# RL6955_IP_SVD register map
Vendor: Realtek
Registers are 32-bit, read-write, reset 0x0 unless marked. A register's access mark holds for its fields unless they carry their own. Offsets are from the block's base; [hi:lo] are bit positions; {n}, {i} and the like mark numbered series; <NAME> marks a mode.

## PSRAM_REG (part 2 of 2)
Base 0x41909000
Same registers: SPI_FLASH_CTRL 0x4190B000
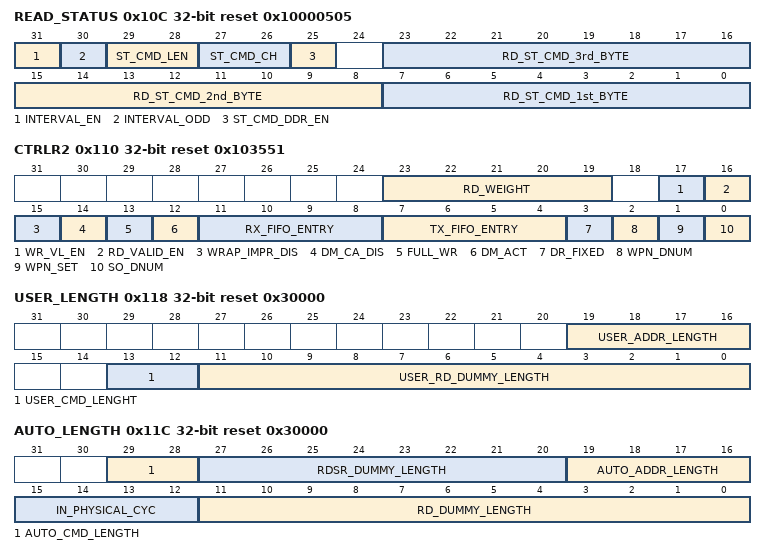
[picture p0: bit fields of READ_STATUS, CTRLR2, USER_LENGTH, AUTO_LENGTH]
0x10C READ_STATUS reset 0x10000505 — Read Status Command of SPI Flash
  [31] INTERVAL_EN — Set to enable INTERVAL_ODD. Available only if configuration of SPIC_LITE is not defined (SPIC Full ver).
  [30] INTERVAL_ODD — Indicates SPI Flash read status with 2-Byte status but checking only odd byte or even byte. 0: even byte (2, 4, 6, ...) 1: odd byte (1, 3, 5, ...) Available only if configuration of SPIC_LITE is not defined (SPIC Full ver).
  [29:28] ST_CMD_LEN — Indicates the number of bytes in read status command. ST_CMD_LEN can be 1~3. Available only if configuration of SPIC_LITE is not defined (SPIC Full ver).
  [27:26] ST_CMD_CH — Indicates channel number of read status command in transmitting and receiving data. 0: single channel 1: dual channels 2: quad channels 3: octal channel
  [25] ST_CMD_DDR_EN — Indicates the DDR mode in ST_CMD_CH. Available only if configuration of DDR_EN is defined.
  [23:16] RD_ST_CMD_3rd_BYTE — Indicates SPI Flash command value of 3rd byte of read status. Available only if configuration of SPIC_LITE is not defined (SPIC Full ver).
  [15:8] RD_ST_CMD_2nd_BYTE — Indicates SPI Flash command value of 2nd byte of read status. Available only if configuration of SPIC_LITE is not defined (SPIC Full ver).
  [7:0] RD_ST_CMD_1st_BYTE — Indicates SPI Flash command value of 1st byte of read status.
0x110 CTRLR2 reset 0x103551 — Control Register 2
  [23:19] RD_WEIGHT — Set to determine the read and write priority. RD_WEIGHT should >= 2 (if set to 0 or 1, RD_WEIGHT will use the previous value). Ex: if RD_WEIGHT = 5, SPIC will accept 1 write cmd after accepting 4 read cmd.
  [17] WR_VL_EN — Set to enable variable write latency. SPIC will set variable write latency according to RWDS. If WR_VL_EN = 0, SPIC will set fix write latency.
  [16] RD_VALID_EN — Set to enable variable read latency. SPIC will not sample read data until rx_data_valid = 1. If RD_VALID_EN = 0, SPIC will sample read data according to internal counter.
  [15] WRAP_IMPR_DIS — Set to disable wrap_align function (convert wrap to incremental through aligning start address to burst boundary) in auto mode. If DIS_WRAP_ALIGN = 1, SPIC will chop wrap transation into two incremental transactions.
  [14] DM_CA_DIS — Set to disable spi_dm_oe_n (let the device to drive DM) when SPIC pushing CMD and ADDR for both user mode and auto mode. Used to implement write variable latency in Winbond psram.
  [13] FULL_WR — Set to enable full write in both user mode and auto mode. If FULL_WR=1, SPIC will ignore pushing DM_DR in user mode. If FULL_WR = 0, SPIC will use spi_dm to do partial write in auto mode. Available only if configuration of DM_EN is defined.
  [12] DM_ACT — DM (Data Mask) is active high or low, which is defined by specific PSRAM SPEC. If DM is active high (DM=1 means "don't write"), DM_ACT should be set to 1 and the corresponding byte of write data will not be written into the PSRAM. Available only if configuration of DM_EN is defined.
  [11:8] RX_FIFO_ENTRY — If using SPIC_HAS_DMA (NO_MERGE_FIFO) SPIC, this field indicates the valid entry of RX FIFO. It is an index of 2 and it should be equal or smaller than 5. The user can modify it to profile with a different entry. Ex: if RX_FIFO entry is 32, RX_FIFO_ENTYR <=5.
  [7:4] TX_FIFO_ENTRY — If using SPIC_HAS_DMA (NO_MERGE_FIFO) SPIC, this field indicates the valid entry of TX_FIFO. If using MERGE_FIFO SPIC, there is only one FIFO is in the SPIC design, and this field indicates the valid entry of the FIFO. It is an index of 2 and it should be equal or smaller than FIFO_ABW. The user can modify it to profile with a different entry. Ex: if FIFO entry is 32, FIFO_ENTYR <=5.
  [3] DR_FIXED — Indicate the AXI FIXED read mode on DR. (after 2021/01). It can only work on address that aligns to request size. Ex: (1) arsize=0, addr[1:0] can be 00, 01, 10, 11 (2) arsize=1, addr[1:0] can be 00, 10 (3) arsize=2, addr[1:0] can be 00. If setting 1, user mode read DR will be FIXED. Otherwise, user mode read DR will be INCR.
  [2] WPN_DNUM — Indicates the WPn input pin of SPI Flash is connected to spi_sout[2]or [3]. If setting 0, it connects to spi_sdata[2]. Otherwise, it connects to spi_sdata[3].
  [1] WPN_SET — To implement write protect function. spi_wen_out and the bit of spi_sout which connects to WPN would be initial to 0. WPN_SET: If setting 1 is protected. Otherwise, is not protected.(Configuration Form is using "WPN_SET_n": If setting 1 is NOT protected. Otherwise, is protected.)
  [0] SO_DNUM — Indicates SO input pin of SPI Flash is connected to spi_sout[0]or [1]. It refers to SPI Flash and also the system connection with SPI_Flash (see 6.1.3) If setting 0, it connects to spi_sout[0] (single-channel connection). Otherwise, it connects to spi_sout[1] (multi-channels connection). (Default is configured to 1to support multi-channel connection)
0x114 FBAUDR reset 0x1 — Fast Baud Rate Select
  [11:0] FSCKDV — Indicate the divider of Fast read command when FAST_RD is setting in user mode or using fast read command in auto mode. The frequency of spi_sclk is derived from: Frequency of spi_sclk = Frequency of bus_clk/(2*FSCKDV).
0x118 USER_LENGTH reset 0x30000
  [19:16] USER_ADDR_LENGTH — Indicates number of bytes in address phase (between command phase and write/read phase) in user mode. If it is set to 4, it will transmit 4-byte Address to support 4-byte address mode in SPI Flash.
  [13:12] USER_CMD_LENGHT — Indicates number of bytes in command phase in user mode. USER_CMD_LENGHT can be 0~3.
  [11:0] USER_RD_DUMMY_LENGTH — Indicates delay cycles for receiving data in user mode (USER_MODE == 1). It is referenced by bus_clk.
0x11C AUTO_LENGTH reset 0x30000 — Auto Address Length Register
  [29:28] AUTO_CMD_LENGTH — Indicate byte numbers of read/write command in auto mode. AUTO_CMD_LENGTH should be 1 or 2 bytes. Note: If set 0, it will transmit 1 byte command to device. Exists: TAG >= 2.0.8.
  [27:20] RDSR_DUMMY_LENGTH — Indicates delay cycles for receiving data after Read Status Register (RDSR) command. (auto write or user mode with auto check) It is referenced by bus_clk.
  [19:16] AUTO_ADDR_LENGTH — Indicates number of bytes address in read/write command in auto mode. AUTO_ADDR_LENGTH should be 1, 2, 3, 4 bytes. If it is set to 4, it will transmit 4-byte Address to support 4-byte address mode in SPI Flash. Note: PRM in auto mode should set VALID_CMD[11] (PRM_EN) with correct AUTO_ADDR_LENGTH.
  [15:12] IN_PHYSICAL_CYC — Indicates how many SPIC CLK (bus_clk) cycles from pad to internal SPIC. It is used in both auto mode and user mode.
  [11:0] RD_DUMMY_LENGTH — Indicates delay cycles for receiving data. It is referenced by bus_clk. Note: Don't include SPIC CLK (bus_clk) cycles from pad to internal SPIC
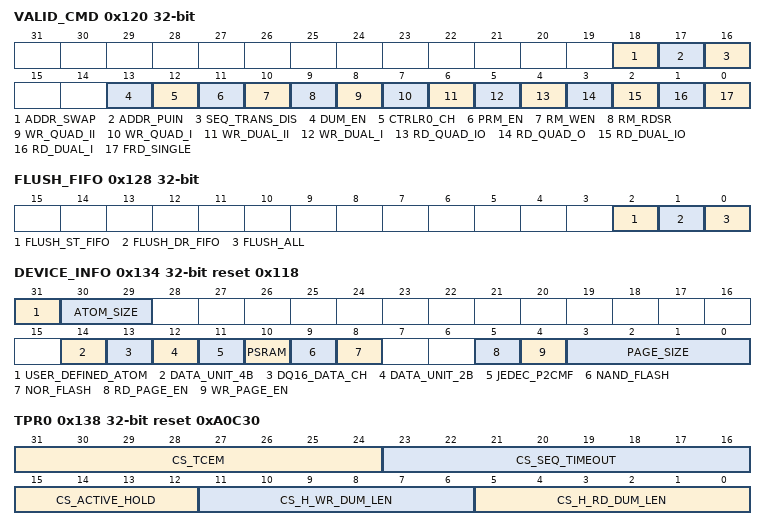
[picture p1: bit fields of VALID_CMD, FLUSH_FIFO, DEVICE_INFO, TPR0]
0x120 VALID_CMD — Valid Command Register
  [18] ADDR_SWAP — Set to enable address swap based on CR.FLASH_SIZE in auto mode If address swap is enable, memory space is divided by two and address will be swapped between two spaces ex. if CR.FLASH_SIZE is 0x9, axi_axaddr is 0x00000000. The real address transmitted to device will be 0x00800000 Exists: TAG >= 2.0.14.
  [17] ADDR_PUIN — Set (1) to pull in first address to negedge of spi_clk. (negedge of last cmd) Set (0) indicate first address start at next posedge of last cmd phase. Used when DDR address and need to pull in address. Exists: TAG >= 2.0.6.
  [16] SEQ_TRANS_DIS — Set (1) to disable sequential read and sequential write function in auto mode. If two bus read/write transactions are sequential (address is consecutive), SPIC can access second transaction data without sending CMD/ADDR/DUMMY. Once disable (1) this bit field, spi_csn will inactive immediately and also disable this function.
  [13] DUM_EN — Enable to push one dummy byte (DUM_BYTE_VAL) after pushing address to Flash in auto read. If PRM_EN is active, it will push PRM_Value instead of DUM_BYTE_VAL. If RD_DUMMY_LENGTH = 0, it won't push the dummy byte.
  [12] CTRLR0_CH — Set (1) to use CTRLR0 CMD_CH/DATA_CH/ADDR_CH and DDR_EN field in Auto mode; Otherwise, SPIC will decode according to which VALID_CMD you choose in auto mode. Suggestion while use this bit field: Read Flash mode: (1-4-8), (4-4-8), (1-4D-8D), (4-4D-8D) with using RD_QUAD_IO[7:0] Read Flash mode (with 2-Byte CMD): (1-8-8), (8-8-8), (8D-8D-8D), (4D-4D-4D) with using RD_FAST_SINGLE_IO[15:0] (always using FBAUD) Write Flash mode: (1-4-8), (4-4-8) with using WR_QUAD_IO[7:0] Write Flash mode (with 2-Byte CMD): (1-8-8), (8-8-8), (8D-8D-8D) with using WR_SINGLE_IO[15:0]
  [11] PRM_EN — Set to enable SPIC performance read mode in Auto Mode. RXI-312 SPIC will auto exit performance read mode before auto write or enter to user mode. Enter PRM Flow: 1. Set CR_VALID_CMD[11] (PRM_EN) with CR_VALID_CMD[4] (RD_QUAD_IO) or with (CR_VALID_CMD[0] and CR_VALID_CMD[12]) 2. Set CR_READ_QUAD_ADDR_DATA[23:16] (PRM_VALUE) and [7:0] (RD_QUAD_IO_CMD) 3. Set correct Dummy Cycle, and Valid Command then access in Auto Mode address range If PRM_EN, at 1st time Auto Rd, it will access with CMD, and store this condition. At 2nd Auto Rd or later, it will access without CMD but with Address and Mode Value. Our SPIC will check PRM_VALUE (CR_READ_QUAD_ADDR_DATA [23:16]), if PRM_VALUE ==00 (not a valid PRM value), and PRM_EN is set, SPIC will always access SPI Flash with (CMD+ADDR+MODE+DUMMY+...) format.
  [10] RM_WEN — Remove write enable command in auto write.
  [9] RM_RDSR — Remove read status register in auto write.
  [8] WR_QUAD_II — Indicates quad address/data write is a valid command to execute. (known as (1-4-4))
  [7] WR_QUAD_I — Indicates quad data write is a valid command to execute. (known as (1-1-4))
  [6] WR_DUAL_II — Indicates dual address/data write is a valid command to execute. (known as (1-2-2))
  [5] WR_DUAL_I — Indicates dual data write is a valid command to execute. (known as (1-1-2))
  [4] RD_QUAD_IO — Indicates quad address/data read is a valid command to execute. (known as (1-4-4))
  [3] RD_QUAD_O — Indicates quad data read is a valid command to execute. (known as (1-1-4))
  [2] RD_DUAL_IO — Indicates dual address/data read is a valid command to execute. (known as (1-2-2))
  [1] RD_DUAL_I — Indicates dual data read is a valid command to execute. (known as (1-1-2))
  [0] FRD_SINGLE — Indicates fast read command is a valid command to execute. (known as (1-1-1))
0x124 FLASE_SIZE reset 0xC — Flash Size Register
  [4:0] FLASH_SIZE — Indicate the size of flash size to select the target SPI Flash in auto mode. (flash size unit is byte) If TAG >= 2.0.3: CR_FLASH_SIZE = log2 (flash size) -15. Ex: flash size is 4MB, CR_FLASH_SIZE = log2 (4MB) -15 = 22 - 15 = 7
0x128 FLUSH_FIFO wo
  [2] FLUSH_ST_FIFO — Clear all data in the ST_FIFO when writing to FLUSH_ST_FIFO register.
  [1] FLUSH_DR_FIFO — Clear all data in the TX_FIFO and RX_FIFO when writing to FLUSH_DR_FIFO register.
  [0] FLUSH_ALL — Clear all data in all FIFO (include TX_FIFO, RX_FIFO and ST_FIFO) and reset all FSM when writing to FLUSH_ALL register.
0x12C DUM_BYTE — Dummy byte value
  [7:0] DUM_BYTE_VAL — Push dummy byte value.
0x130 TX_NDF
  [23:0] TX_NDF — Indicates a number of data frames (Unit: Byte). After transmitting command and address, SPIC transmits data continuously until data frames are equal to TX_NDF. TX_NDF can set larger than TX_FIFO size.
0x134 DEVICE_INFO reset 0x118
  [31] USER_DEFINED_ATOM — Enable user defined DEVICE_INFO[30:29].ATOM_SIZE 1: users can program ATOM_SIZE 0: SPIC sets ATOM_SIZE dynamically Exists: TAG >= 2.0.12.
  [30:29] ATOM_SIZE — Indicate the atomic size of read/write transactions 2'b00: 1 byte 2'b01: 2 byte 2'b10: 4 byte 2'b11: 3 byte The equation of atomic size: data_channel * data_rate e.g., if DQ16 and DDR, atomic size is (16*2/8) = 4 byte *Minimun atomic size is 1 byte *For exception of this equaltion, refer to PSRAM Format for devices with special requirements For TAG < 2.0.12, ATOM_SIZE is [7:6] and is set automatically by SPIC
  [14] DATA_UNIT_4B — Set (1) when the SPI device stores 4-byte data for each address. Available only if configuration of PSRAM_EN is defined.
  [13] DQ16_DATA_CH — Set (1) when DQ16 PSRAM uses 16-bit data channel. When DQ16_DATA_CH = 1'b1, set CTRLR0[19:18] DATA_CH = 2'b00.
  [12] DATA_UNIT_2B — Set (1) when the SPI device stores 2-byte data for each address. Available only if configuration of PSRAM_EN is defined.
  [11] JEDEC_P2CMF — Set (1) when the SPI cmd is JEDEC Profile 2.0 Command Modifier Formats. (6-byte command and address) Available only if configuration of PSRAM_EN is defined.
  [10] PSRAM — Set (1) when the SPI device is PSRAM. PSRAM will disable WEN and RDSR in auto write. Available only if configuration of PSRAM_EN is defined.
  [9] NAND_FLASH — Set (1) when the SPI device is NAND Flash. (not support yet) Available only if configuration of NAND_EN is defined.
  [8] NOR_FLASH — Set (1) when the SPI device is NOR Flash.
  [5] RD_PAGE_EN — Enable SPIC to chop the burst read command across page boundaries in auto mode.
  [4] WR_PAGE_EN — Enable SPIC to chop the burst write command across page boundaries in auto mode.
  [3:0] PAGE_SIZE — The page size of device (byte) = 2^(PAGE_SIZE) The minimum value of page size is 128-byte. Please set PAGE_SIZE >= 7. ex. If the page size of device is 256-byte, PAGE_SIZE should be set to 8. 0x7: 128-byte 0x8: 256-byte 0x9: 512-byte 0xa: 1024-byte 0xb: 2048-byte 0xc: 4096-byte
0x138 TPR0 reset 0xA0C30 — Timing parameters
  [31:24] CS_TCEM — Set to chop auto cmd when CSN low pulse width = (CS_TCEM*32) bus_clk. If set CS_TCEM = 0 will disable this function. ex. PSRAM tCEM = 4us, SPIC frequency = 100Mhz. CS_TCEM = ((4000 ns/10 ns)/32) - BYTE_DELAY = 12 (c) - BYTE_DELAY If ((16*baud_rate)/data_channel) <=32. BYTE_DELAY = 0. If ((16*baud_rate)/data_channel) > 32. BYTE_DELAY = (((16*baud_rate)/data_channel) - 32)/32. ex. If baud_rate = 3, data_channel = 1. BYTE_DELAY = (((16*3)/1) - 32)/32 = 16/32 = 0.5 Therefore, BYTE_DELAY should be 1 in this example. Note: Available only if configuration of PSRAM_EN is defined.
  [23:16] CS_SEQ_TIMEOUT — The timeout setting of auto command after sequential read command. If set CS_SEQ_TIMEOUT = 00 will disable this function. If set CS_SEQ_TIMEOUT > 00, SPIC will exit sequential transaction read and inactive CS when there is no auto read/write command for (CS_SEQ_TIMEOUT *4) bus_clocks.
  [15:12] CS_ACTIVE_HOLD — For Flash chip select active hold time after SCLK rising edge (refer to tSLCH/CHSH, tCSS/tCSH) Note: Wait most 16 bus_clk cycles before CS inactive. (Implement CS_ACTIVE_Hold timing only, CS_ACTIVE_Setup timing using D-PHY to shift)
  [11:6] CS_H_WR_DUM_LEN — Dummy cycle between sending write command to SPI Flash. Using the dummy cycles to avoid the timing violation of CS high time.
  [5:0] CS_H_RD_DUM_LEN — Dummy cycle between sending read command to SPI Flash. Using the dummy cycles to avoid the timing violation of CS high time.
0x13C AUTO_LENGTH2 — Auto Address Length Register 2
  [11:0] WR_DUMMY_LENGTH — Indicates delay cycles for transmitting data in auto mode. It is referenced by bus_clk. Available only if configuration of PSRAM_EN is defined.
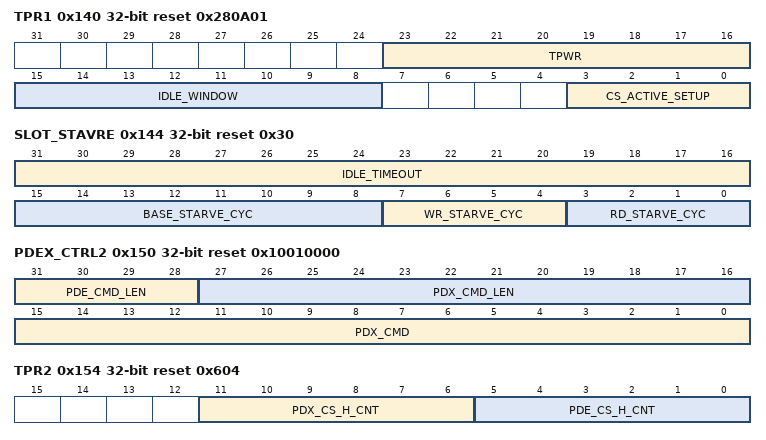
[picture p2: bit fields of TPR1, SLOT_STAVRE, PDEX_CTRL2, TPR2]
0x140 TPR1 reset 0x280A01 — Timing Parameters Register 1
  [23:16] TPWR — It is used to configure the cycle counts before spi_csn becomes low when spi_pwr turns from low to high.
  [15:8] IDLE_WINDOW — It is used to configure the cycle counts before turn off the spi_pwr when SPIC is IDLE.
  [3:0] CS_ACTIVE_SETUP — It is used to configure the setup time before the first edge (rising edge for mode0 and falling edge for mode3) of spi_sclk(refer to tCSS or tSLCH ). Note: It can't be configured 0 (if you configure 0 to this 4 bits field, this field will not be updated).
0x144 SLOT_STAVRE reset 0x30 — Slot Starvation Control Register
  [31:16] IDLE_TIMEOUT — If the current slot has no command and another slot has command, or both write/read slot have no command and current slot is write slot, to wait IDLE_TIMEOUT cycles and turnaround slot if current slot still has no command Exists: TAG >= 2.0.5.
  [15:8] BASE_STARVE_CYC — This is basic starvation counter cycles for WR_STARVE_CYC and RD_STARVE_CYC. Exists: TAG >= 2.0.5.
  [7:4] WR_STARVE_CYC — The timeout of write slot would be set when write cmd is no servicing in the interval time= (WR_STARVE_CYC+1) x (BASE_STARVE_CYC+1) Exists: TAG >= 2.0.5.
  [3:0] RD_STARVE_CYC — The timeout of read slot would be set when read cmd is no servicing in the interval time= (RD_STARVE_CYC+1) x (BASE_STARVE_CYC+1) Exists: TAG >= 2.0.5.
0x148 PDEX_CTRL0 — PDEX Control Register 0
  [31:0] PDE_CMD0 — Indicate the [3-0] byte of SPI PDE command value. Exists: TAG >= 2.0.5. Available only if configuration of SPI_PDEX_ENABLE is defined.
0x14C PDEX_CTRL1 — PDEX Control Register 1
  [31:0] PDE_CMD1 — Indicate the [7-4] byte of SPI PDE command value. Exists: TAG >= 2.0.5. Available only if configuration of SPI_PDEX_ENABLE is defined.
0x150 PDEX_CTRL2 reset 0x10010000 — PDEX Control Register 2
  [31:28] PDE_CMD_LEN — Indicate the SPI PDE command length. The PDE command length indicates the valid command in PDE_CMD0 and PDE_CMD1 Exists: TAG >= 2.0.5. Available only if configuration of SPI_PDEX_ENABLE is defined.
  [27:16] PDX_CMD_LEN — Indicate the SPI PDX command length. The PDE command length indicates the valid command in PDX_CMD. If device is PSRAM, the equation is CR_PDX_CMD_LEN = (SPIC_CLK_FRQ * tXDPD)/1000. (SPIC_CLK_FRQ unit is MHz, tXDPD unit is ns) Exists: TAG >= 2.0.5. Available only if configuration of SPI_PDEX_ENABLE is defined.
  [15:0] PDX_CMD — Indicate the [1-0] byte of SPI PDX command value. If device is PSRAM, PDX command value is not care. Exists: TAG >= 2.0.5. Available only if configuration of SPI_PDEX_ENABLE is defined.
0x154 TPR2 reset 0x604 — Timing Parameters Register 2
  [11:6] PDX_CS_H_CNT — Indicate the time of cs required keep high after PDX The expression of PDX_CS_H_CNT is following PDX_CYCLE_NUM = SPIC_CLK_FRQ * tDP (unit of SPIC_CLK_FRQ is MHz, and tDP is us). If 768>=PDX_CYCLE_NUM > 0, CR_PDX_CS_H_CNT = ceil (PDE_CYCLE_NUM/256). If 15872>=PDX_CYCLE_NUM > 768, CR_PDX_CS_H_CNT = ceil (PDE_CYCLE_NUM/512). If 524288>=PDX_CYCLE_NUM > 15872, CR_PDX_CS_H_CNT = ceil (PDE_CYCLE_NUM/16384) + 31. Ex: SPIC_CLK_FRQ = 400MHz, tDP = 100us, so PDX_CYCLE_NUM = 400*100=40000 524288 >= 40000 > 15872, so CR_PDX_CS_H_CNT = ceil(40000/512) + 31= 3+31 = 34. Exists: TAG >= 2.0.5. Available only if configuration of SPI_PDEX_ENABLE is defined.
  [5:0] PDE_CS_H_CNT — Indicate the time of cs required keep high after PDE The expression of PDE_CS_H_CNT is following PDE_CYCLE_NUM = SPIC_CLK_FRQ * tDP ( unit of SPIC_CLK_FRQ is MHz, and tDP is us). If 768>=PDX_CYCLE_NUM > 0, CR_PDX_CS_H_CNT = ceil (PDE_CYCLE_NUM/256). If 15872>=PDX_CYCLE_NUM > 768, CR_PDX_CS_H_CNT = ceil (PDE_CYCLE_NUM/512). If 524288>=PDX_CYCLE_NUM > 15872, CR_PDX_CS_H_CNT = ceil (PDE_CYCLE_NUM/16384) + 31. Ex: SPIC_CLK_FRQ = 400MHz, tDP = 100us, so PDX_CYCLE_NUM = 400*100=40000 524288 >= 40000 > 15872, so CR_PDX_CS_H_CNT = ceil(40000/512) + 31= 3+31 = 34. Exists: TAG >= 2.0.5. Available only if configuration of SPI_PDEX_ENABLE is defined.
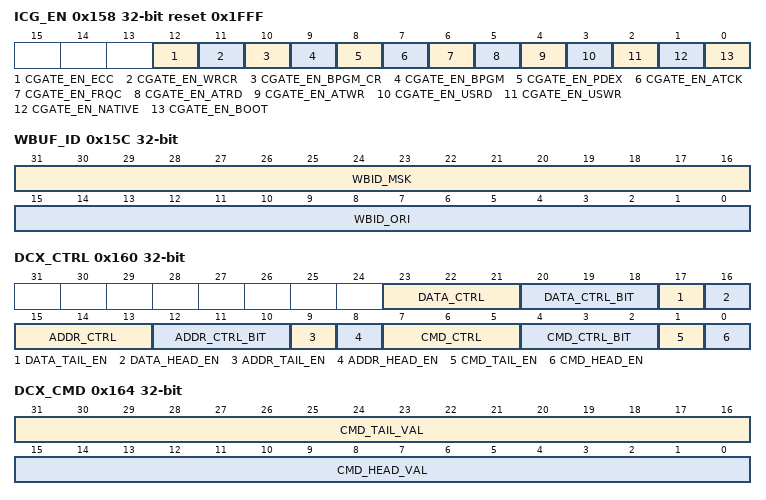
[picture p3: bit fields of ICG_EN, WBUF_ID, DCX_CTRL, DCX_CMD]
0x158 ICG_EN reset 0x1FFF — Clock gating enable control register
  [12] CGATE_EN_ECC — Nand ECC controller module clock gating enable. Exists: TAG >= 2.0.11
  [11] CGATE_EN_WRCR — Write cr module clock gating enable
  [10] CGATE_EN_BPGM_CR — bpgm_cr module clock gating enable
  [9] CGATE_EN_BPGM — bpgm module clock gating enable
  [8] CGATE_EN_PDEX — pdex module clock gating enable
  [7] CGATE_EN_ATCK — atck module clock gating enable
  [6] CGATE_EN_FRQC — frqc module clock gating enable
  [5] CGATE_EN_ATRD — Auto read module clock gating enable
  [4] CGATE_EN_ATWR — Auto write module clock gating enable
  [3] CGATE_EN_USRD — User read module clock gating enable
  [2] CGATE_EN_USWR — User write module clock gating enable
  [1] CGATE_EN_NATIVE — Native chop module clock gating enable
  [0] CGATE_EN_BOOT — Boot module clock gating enable
0x15C WBUF_ID — WBUF ID control register
  [31:16] WBID_MSK — WBID_ORI bit mask. 0: Interrupt bit is masked. 1: Interrupt bit enable.
  [15:0] WBID_ORI — Indicate the awid prior mask are able to push to WBUF in write buffer function. Example: If awid = 0x80 ~ 0x8f are able to push to WBUF. Set WBID_ORI = 0x80 Set WBID_MSK = 0xfff0
0x160 DCX_CTRL — LCDC DCX control register
  [23:21] DATA_CTRL — This field can only be active when DATA_CTRL_BIT is not 0. 0: only one DCX control bit in data phase; 1: DCX control bit for each byte in data phase; 2: DCX control bit for every 2-byte in data phase; 3: DCX control bit for every 4-byte in data phase; 4: DCX control bit for every 8-byte in data phase; 5: DCX control bit for every 16-byte in data phase;
  [20:18] DATA_CTRL_BIT — DCX control bit for data phase. 0: independent DCX signal 1: DCX control bit = 1-bit; 2: DCX control bit = 2 bit; 3: DCX control bit = 4-bit; 4: DCX control bit = 8-bit; 5: DCX control bit = 16-bit;
  [17] DATA_TAIL_EN — 0: without tail in data phase 1: insert tail in data phase
  [16] DATA_HEAD_EN — 0: without header in data phase 1: insert header in data phase
  [15:13] ADDR_CTRL — This field can only be active when ADDR_CTRL_BIT is not 0. 0: only one DCX control bit in addr phase; 1: DCX control bit for each byte in addr phase; 2: DCX control bit for every 2-byte in addr phase; 3: DCX control bit for every 4-byte in addr phase; 4: DCX control bit for every 8-byte in addr phase; 5: DCX control bit for every 16-byte in addr phase;
  [12:10] ADDR_CTRL_BIT — DCX control bit for addr phase. 0: independent DCX signal 1: DCX control bit = 1-bit; 2: DCX control bit = 2 bit; 3: DCX control bit = 4-bit; 4: DCX control bit = 8-bit; 5: DCX control bit = 16-bit;
  [9] ADDR_TAIL_EN — 0: without tail in address phase 1: insert tail in address phase
  [8] ADDR_HEAD_EN — 0: without header in address phase 1: insert header in address phase
  [7:5] CMD_CTRL — This field can only be active when CMD_CTRL_BIT is not 0. 0: only one DCX control bit in cmd phase; 1: DCX control bit for each byte in cmd phase; 2: DCX control bit for every 2-byte in cmd phase; 3: DCX control bit for every 4-byte in cmd phase; 4: DCX control bit for every 8-byte in cmd phase; 5: DCX control bit for every 16-byte in cmd phase;
  [4:2] CMD_CTRL_BIT — DCX control bit for cmd phase. 0: independent DCX signal 1: DCX control bit = 1-bit; 2: DCX control bit = 2 bit; 3: DCX control bit = 4-bit; 4: DCX control bit = 8-bit; 5: DCX control bit = 16-bit;
  [1] CMD_TAIL_EN — 0: without tail in cmd phase 1: insert tail in cmd phase
  [0] CMD_HEAD_EN — 0: without header in cmd phase 1: insert header in cmd phase
0x164 DCX_CMD — LCDC cmd phase DCX control bit value register
  [31:16] CMD_TAIL_VAL — Value of DCX tail control bit in cmd phase.
  [15:0] CMD_HEAD_VAL — Value of DCX header control bit in cmd phase. In 4-wire format cmd phase, spi_dcx = CMD_HEAD_VAL[0].
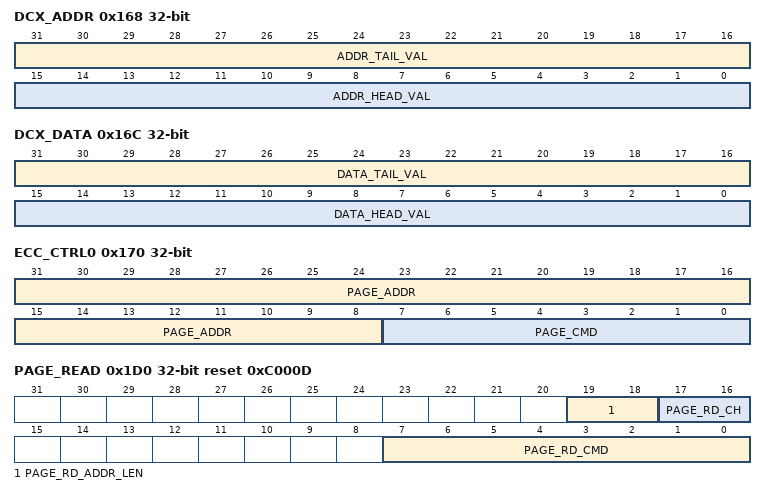
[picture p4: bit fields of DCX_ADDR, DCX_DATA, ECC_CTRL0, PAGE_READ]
0x168 DCX_ADDR — LCDC address phase DCX control bit value register
  [31:16] ADDR_TAIL_VAL — Value of DCX tail control bit in address phase.
  [15:0] ADDR_HEAD_VAL — Value of DCX header control bit in address phase. In 4-wire format address phase, spi_dcx = ADDR_HEAD_VAL[0].
0x16C DCX_DATA — LCDC data phase DCX control bit value register
  [31:16] DATA_TAIL_VAL — Value of DCX tail control bit in data phase.
  [15:0] DATA_HEAD_VAL — Value of DCX header control bit in data phase. In 4-wire format data phase, spi_dcx = DATA_HEAD_VAL[0].
0x170 ECC_CTRL0 — NAND ECC control Register 0
  [31:8] PAGE_ADDR — NAND Page address setting. Exists: TAG >= 2.0.11
  [7:0] PAGE_CMD — NAND page command setting. Ex. READ: Page Data Read (13h) WRITE: Page Execute (10h) Exists: TAG >= 2.0.11
0x174 ECC_CTRL1 — NAND ECC control Register 1
  [7:0] DATA_CMD — NAND data command setting. Ex. READ: Read data (03h) WRITE: Load Program Data (02h) Exists: TAG >= 2.0.11
{0x180+4i} ST_DR{i} ro (i=0..15) — Status Data Register {i}
  [7:0] ST_DR{i} — It is a data buffer with 8-bit width FIFO.
0x1C0 STFLR ro — Status FIFO level Register
  [3:0] STFLR — Status FIFO level. Indicates the FIFO entries of valid data in status data. Note: Available only if configuration of NAND_EN is defined.
0x1D0 PAGE_READ reset 0xC000D — Page Read Command of NAND Flash
  [19:18] PAGE_RD_ADDR_LEN — Indicates number of bytes in address phase in page read command. Available only if configuration of NAND_EN is defined.
  [17:16] PAGE_RD_CH — Indicates channel number of command and address phase in transmitting page read command. 0: single channel 1: dual channels 2: quad channels 3: octal channel Available only if configuration of NAND_EN is defined.
  [7:0] PAGE_RD_CMD — Indicates SPI Flash command value of page read command Available only if configuration of NAND_EN is defined.
{0x200+0xC*i} SEC_BASE_{i} (i=0..7) — SEC region {i} base address register
  [31:12] SEC_BASE{i} — SEC region {i} base address[31:12]. This is 4KB aligned address. Note: Available only if configuration of PSRAM_EN is defined.
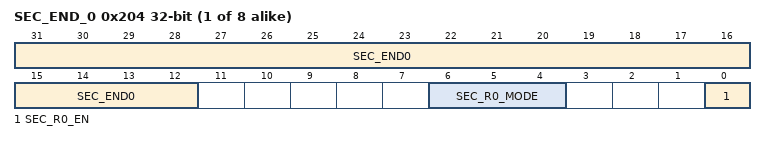
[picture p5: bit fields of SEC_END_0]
{0x204+0xC*i} SEC_END_{i} (i=0..7) — SEC region {i} end address register
  [31:12] SEC_END{i} — SEC region {i} end address[31:12]. This is 4KB aligned address. Note: Available only if configuration of PSRAM_EN is defined.
  [6:4] SEC_R{i}_MODE — SEC region {i} - function mode/seed selection. Select one of mode/seed from SEC_NONCE0~SEC_NONCE7
  [0] SEC_R{i}_EN — Set to enable SEC region {i} to scramble write data and descramble read data.
{0x208+0xC*i} SEC_NONCE_{i} (i=0..7) — SEC region {i} nonce register
  [31:0] SEC_NONCE{i} — Only present if SEC_CONF_MODE > 0. Seed of scrambler mode {i}. This register value cannot be 0, otherwise the encrypted data will be equal to the original data. Note: Available only if configuration of PSRAM_EN is defined.
0x3FC SEC_IDR ro — SEC ID register
